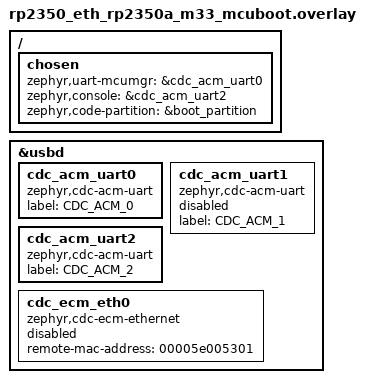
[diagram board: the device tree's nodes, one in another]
#include <vendor/raspberrypi/rp2350-boot-mode-retention.dtsi>

/ {
	chosen {
		zephyr,uart-mcumgr = &cdc_acm_uart0;
		zephyr,console = &cdc_acm_uart2;
		zephyr,code-partition = &boot_partition;
	};
};


zephyr_udc0: &usbd {
	//compatible = "raspberrypi,rp-usbd";
	status = "okay";
	cdc_acm_uart0: cdc_acm_uart0 {
		status = "okay";
		compatible = "zephyr,cdc-acm-uart";
		label = "CDC_ACM_0";
	};
	cdc_acm_uart1: cdc_acm_uart1 {
		status = "disabled";
		compatible = "zephyr,cdc-acm-uart";
		label = "CDC_ACM_1";
	};
	cdc_acm_uart2: cdc_acm_uart2 {
		status = "okay";
		compatible = "zephyr,cdc-acm-uart";
		label = "CDC_ACM_2";
	};
	cdc_ecm_eth0: cdc_ecm_eth0 {
		status = "disabled";
		compatible = "zephyr,cdc-ecm-ethernet";
		remote-mac-address = "00005e005301";
	};
};
